# VCP1_L4_PER2Interconnect register map
Vendor: Texas Instruments
Peripheral module from a debugger description file (folder DRA74xP_75xP_76xP_77xP).
Registers are 32-bit, access per field, reset 0x0 unless marked. A register's access mark holds for its fields unless they carry their own. Offsets are as the file gives them; lines under a group give offsets from that group; [hi:lo] are bit positions; {n}, {i} and the like mark numbered series; 'fields as' and 'values as' point back to an identical list; <NAME> marks a mode.

## VCP1_L4_PER2Interconnect
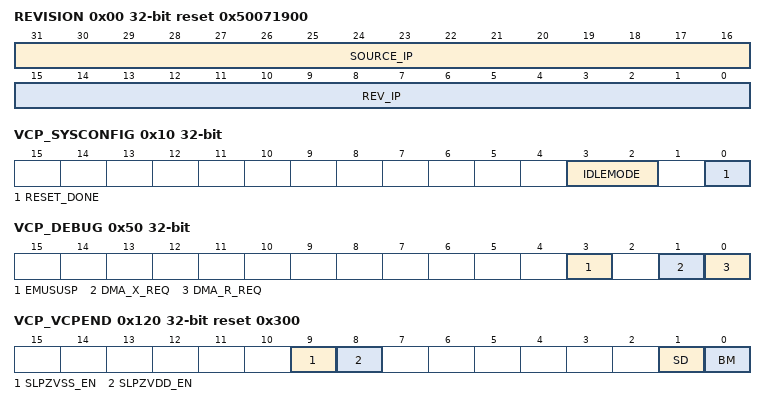
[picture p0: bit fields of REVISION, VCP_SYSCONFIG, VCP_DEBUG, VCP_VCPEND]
0x00 REVISION ro reset 0x50071900 — VCP version 2 - IP Revision Register is used to track the version of the IP.
  [31:16] SOURCE_IP — Source of VCP IP
  [15:0] REV_IP — VCP IP Revision number
0x10 VCP_SYSCONFIG — System Configuration Register is used to set the idle modes for the VCP modules
  [3:2] IDLEMODE rw — Idle mode bit
    0=Idle request unconditionally acknowledged (ack = req); 1=Acknowledge_always_inactive_(ack=0); 2=Idle request acknowledge pending internal conditions
  [0] RESET_DONE ro — Reset done is a read only and shows the status of the reset from the idle command.
0x20 VCP_IRQ_EOI — End of interrupt register.
  [0] LINE_NUMBER wo — Software End of Interrupt (EOI) control. Write a value of 0x0 to repulse the interrupt output if any interrupts are pending.
0x28 VCP_IRQSTATUS — IRQ status register captures the current active status of the interrupts after the enabling function.
  [0] STATUS rw — VCP IRQ enable status
    0=VCP_error_interrupt_is_not_enabled; 1=VCP_error_interrupt_is_enabled
0x2C VCP_IRQENABLE_SET — The VCP set enable interrupt register allows the user to enable the VCP error interrupt. The software should enable the interrupt on the VCP by writing writing a 1 to bit 0 of the IRQENABLE_SET register.
  [0] ENABLE_SET rw — VCP IRQ enable status
    0=VCP_error_interrupt_is_disabled; 1=VCP_error_interrupt_is_enabled
0x30 VCP_IRQENABLE_CLR — The VCP clear enable interrupt register allows the user to disable the VCP error interrupt.
  [0] ENABLE_CLR rw — VCP IRQ enable status
    0=No_effect; 1=VCP_error_interrupt_is_disabled
0x50 VCP_DEBUG ro — Debug Configuration Register is used to view that status of various events in the VCP1 and VCP2 including emulation suspend mode request and DMA status for read and write requests.
  [3] EMUSUSP — Status of the emulation suspend mode request
    0=Emulation suspend mode request has not been sent; 1=Emulation suspend mode requrest has been sent
  [1] DMA_X_REQ — Status of the VCP tranmit event (VCPnXEVT)
    0=DMA_0 (No transmit DMA (write) event is pending); 1=Transmit_DMA_(write)_event_is_pending
  [0] DMA_R_REQ — Status of the VCP receive event (VCPnREVT)
    0=No_receive_DMA_(read)_event_is_pending; 1=Receive_DMA_(read)_event_is_pending
0x118 VCP_VCPEXE — VCP version 2 execution register
  [3:0] COMMAND wo — VCP command select bits:
    1=Start_VCP_(normal_mode); 2=VCP_VCP_2 (Halt or Pause VCP (debug mode). The VCP is halted (or paused) after processing the state metric for the current sliding window and before the start of the traceback.); 3=VCP_VCP_VCP_3 (Restart VCP and process one sliding window (debug mode). The VCP is restarted from the pause state and begins the traceback operation. The VCP is again paused after processing the state metrics for next sliding window.); 4=VCP_VCP_VCP_4 (Restart VCP (debug mode). The VCP is restarted from the paused state and begins the traceback operation. The VCP will run to normal completion.); 5=VCP_VCP_5 (Stop. Soft reset all VCP registers to their initial condition. All registers in the VCP are reset in this mode except for the execution register, endian register, emulation register, and other internal registers.)
0x120 VCP_VCPEND reset 0x300 — VCP Endian Mode Register
  [9] SLPZVSS_EN rw — Sleep mode for SLPZVSS_EN
    0=Programed_for_proper_operation
  [8] SLPZVDD_EN rw — Sleep mode for SLPZVDD_EN
    0=Programed_for_proper_operation
  [1] SD rw — Traceback soft-decision memory format select bit.
    0=32-bit-word_packed; 1=Native_format_(8_bits)
  [0] BM rw — Branch metrics memory format select bit.
    0=32-bit-word_packed; 1=Native_format_(8_bits)
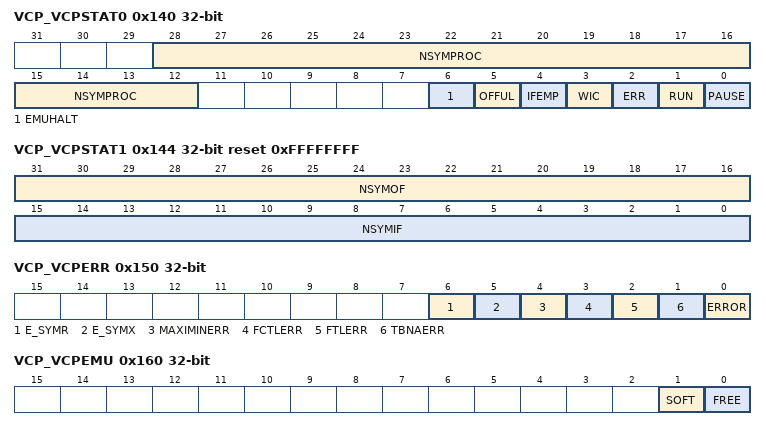
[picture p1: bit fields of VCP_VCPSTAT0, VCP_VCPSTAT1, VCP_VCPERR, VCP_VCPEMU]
0x140 VCP_VCPSTAT0 ro — VCP Status Register 0
  [28:12] NSYMPROC — Number of symbols processed bits. The NSYMPROC bits indicate how many symbols have been processed in the state metric unit with respect to time. The maximum number of processed stages is equal to F + (k-1) in tailed or mixed mode. The maximum number of processed stages is equal toF + C in convergent mode.
  [6] EMUHALT — Emulation halt status bit
    0=No_halt_due_to_emulation; 1=Halt_due_to_emulation
  [5] OFFUL — Output FIFO buffer full status bit
    0=Output_FIFO_buffer_is_not_full; 1=Output_FIFO_buffer_is_full
  [4] IFEMP — Input FIFO buffer empty status bit
    0=Input_FIFO_buffer_is_not_empty; 1=Input_FIFO_buffer_is_empty
  [3] WIC — Waiting for input configuration bit. The WIC bit indicates that the VCP is waiting for new input control parameters to be written. This bit is always set after decoding of a user channel.
    0=Not waiting for input configuration words; 1=Waiting_for_input_configuration_words
  [2] ERR — VCP error status bit. The ERR bit is cleared as soon as the DSP reads the VCP error register (VCPERR).
    0=No_error; 1=VCP_paused_due_to_error
  [1] RUN — VCP running status bit
    0=VCP_is_not_running; 1=VCP_is_running
  [0] PAUSE — VCP pause status bit
    0=VCP_UNPAUSE_PAUSE_0 (VCP is not paused. The UNPAUSE command is acknowledged by clearing the PAUSE bit.); 1=VCP_PAUSE_PAUSE_PAUSE_FIFO_FIFO_1 (VCP is paused. The PAUSE command is acknowledged by setting the PAUSE bit. The PAUSE bit can also be set, if the input FIFO buffer is becoming empty or if the output FIFO buffer is full.)
0x144 VCP_VCPSTAT1 ro reset 0xFFFFFFFF — VCP Status Register 1
  [31:16] NSYMOF — Number of symbols in the output FIFO buffer.
  [15:0] NSYMIF — Number of symbols in the input FIFO buffer.
0x150 VCP_VCPERR ro — VCP Error Register
  [6] E_SYMR — SMAR error
    0=No_error_for_SMAR; 1=Error
  [5] E_SYMX — SMAX Error
    0=No_error_for_SMAX; 1=Error
  [4] MAXIMINERR — MAXIMIN ERROR
    0=No_error; 1=Error
  [3] FCTLERR — FCTL error
    0=No_error; 1=R_C)_(R_1 (1 = r + c too large (( R + C) > (R + C)max) for mixed or convergent traceback modes)
  [2] FTLERR — FTL Error
    0=No_error; 1=F_(F_1 (F too large (F > Fmax) for tailed traceback mode)
  [1] TBNAERR — TBNA Error
    0=No_error; 1=Traceback_mode_is_not_allowed
  [0] ERROR
    0=No_error_is_detected; 1=An_error_has_occurred
0x160 VCP_VCPEMU — VCP Emulation Control Register
  [1] SOFT rw — Soft bit
    0=VCP_0 (Default mode - VCP completes the current window of state metric processing and halts before starting traceback or at the end of a frame); 1=VCP_1 (VCP completes a frame of data before halting)
  [0] FREE rw — Free bit
    0=SOFT_bit_takes_effect; 1=Free run mode - peripheral ignores the vcp_emususp signal and functions normally
